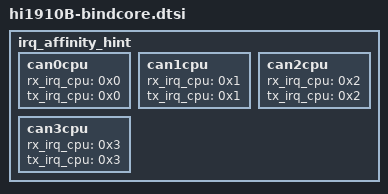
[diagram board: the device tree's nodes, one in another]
/**
 * Define the cores for irq to set affinity hint.
 * You can add the cores in the following "<>", split with space.
 */
irq_affinity_hint {
    /* drv_mttcan */
    can0cpu: can0cpu {
        rx_irq_cpu = <0x0>;
        tx_irq_cpu = <0x0>;
    };
    can1cpu: can1cpu {
        rx_irq_cpu = <0x1>;
        tx_irq_cpu = <0x1>;
    };
    can2cpu: can2cpu {
        rx_irq_cpu = <0x2>;
        tx_irq_cpu = <0x2>;
    };
    can3cpu: can3cpu {
        rx_irq_cpu = <0x3>;
        tx_irq_cpu = <0x3>;
    };
};
